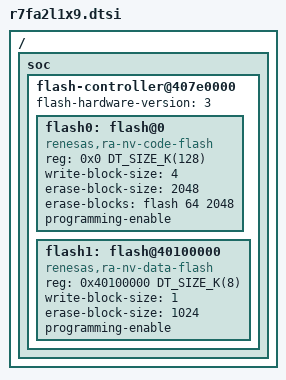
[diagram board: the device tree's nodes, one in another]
/**
 * Copyright (c) 2024 MUNIC SA
 *
 * Renesas R7FA2AL1x9 MCU device tree
 *
 * SPDX-License-Identifier: Apache-2.0
 *
 */

/ {
	soc {
		flash-controller@407e0000 {
			flash-hardware-version = <3>;
			#erase-block-cells = <2>;

			flash0: flash@0 {
				compatible = "renesas,ra-nv-code-flash";
				reg = <0x0 DT_SIZE_K(128)>;
				write-block-size = <4>;
				erase-block-size = <2048>;
				erase-blocks = <&flash 64 2048>;
				programming-enable;
			};

			flash1: flash@40100000 {
				compatible = "renesas,ra-nv-data-flash";
				reg = <0x40100000 DT_SIZE_K(8)>;
				write-block-size = <1>;
				erase-block-size = <1024>;
				programming-enable;
			};
		};
	};
};
